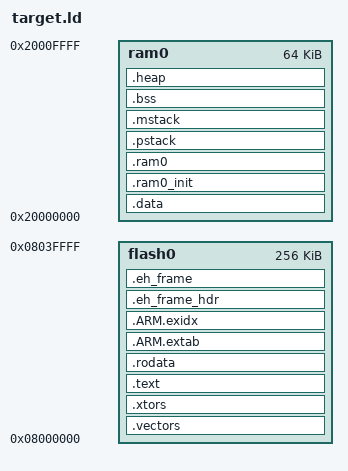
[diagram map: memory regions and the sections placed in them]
/*
    ChibiOS - Copyright (C) 2006..2016 Giovanni Di Sirio

    Licensed under the Apache License, Version 2.0 (the "License");
    you may not use this file except in compliance with the License.
    You may obtain a copy of the License at

        http://www.apache.org/licenses/LICENSE-2.0

    Unless required by applicable law or agreed to in writing, software
    distributed under the License is distributed on an "AS IS" BASIS,
    WITHOUT WARRANTIES OR CONDITIONS OF ANY KIND, either express or implied.
    See the License for the specific language governing permissions and
    limitations under the License.
*/

MEMORY
{
    flash0  : org = 0x08000000, len = 256k
    ram0    : org = 0x20000000, len = 64k
}

__ram0_start__          = ORIGIN(ram0);
__ram0_size__           = LENGTH(ram0);
__ram0_end__            = __ram0_start__ + __ram0_size__;
__main_stack_size__     = 0x400;
__process_stack_size__  = 0x400;

ENTRY (Reset_Handler)

SECTIONS
{
    .vectors : ALIGN(16)
    {
        KEEP(*(.vectors))
    } > flash0

    .xtors : ALIGN(4)
    {
        __init_array_start = .;
        KEEP(*(SORT(.init_array.*)))
        KEEP(*(.init_array))
        __init_array_end = .;
        __fini_array_start = .;
        KEEP(*(.fini_array))
        KEEP(*(SORT(.fini_array.*)))
        __fini_array_end = .;
    } > flash0

    .text : ALIGN(16)
    {
        *(.text)
        *(.text.*)
        *(.glue_7t)
        *(.glue_7)
        *(.gcc*)
    } > flash0

    .rodata : ALIGN(4)
    {
        . = ALIGN(4);
        __rodata_base__ = .;
        *(.rodata)
        *(.rodata.*)
        . = ALIGN(4);
        __rodata_end__ = .;
    } > flash0

    .ARM.extab :
    {
        *(.ARM.extab* .gnu.linkonce.armextab.*)
    } > flash0

    .ARM.exidx : {
        __exidx_start = .;
        *(.ARM.exidx* .gnu.linkonce.armexidx.*)
        __exidx_end = .;
     } > flash0

    .eh_frame_hdr :
    {
        *(.eh_frame_hdr)
    } > flash0

    .eh_frame : ONLY_IF_RO
    {
        *(.eh_frame)
    } > flash0

    _eoflash0 = .;

    .data : AT(_eoflash0) ALIGN(4)
    {
        . = ALIGN(4);
        PROVIDE(_textdata = LOADADDR(.data));
        PROVIDE(_data = .);
        _textdata_start = LOADADDR(.data);
        _data_start = .;
        *(.data)
        *(.data.*)
        *(.ramtext)
        . = ALIGN(4);
        PROVIDE(_edata = .);
        _data_end = .;
    } > ram0

    .ram0_init : AT(_eoflash0 + SIZEOF(.data)) ALIGN(4)
    {
        . = ALIGN(4);
        _data_size = SIZEOF(.data);
        __ram0_init_text__ = LOADADDR(.ram0_init);
        __ram0_init__ = .;
        KEEP(*(.ram0_init))
        KEEP(*(.ram0_init.*))
        . = ALIGN(4);
        __ram0_init_end__ = .;
    } > ram0

    .ram0 (NOLOAD) : ALIGN(4)
    {
        . = ALIGN(4);
        __ram0_clear__ = .;
        *(.ram0_clear)
        *(.ram0_clear.*)
        . = ALIGN(4);
        __ram0_noinit__ = .;
        *(.ram0)
        *(.ram0.*)
        . = ALIGN(4);
        __ram0_free__ = .;
    } > ram0

    .pstack :
    {
        . = ALIGN(8);
        __process_stack_base__ = .;
        __main_thread_stack_base__ = .;
        . += __process_stack_size__;
        . = ALIGN(8);
        __process_stack_end__ = .;
        __main_thread_stack_end__ = .;
    } > ram0

    .mstack :
    {
        . = ALIGN(8);
        __main_stack_base__ = .;
        . += __main_stack_size__;
        . = ALIGN(8);
        __main_stack_end__ = .;
    } > ram0

    .bss (NOLOAD) : ALIGN(4)
    {
        . = ALIGN(4);
        _bss_start = .;
        *(.bss)
        *(.bss.*)
        *(COMMON)
        . = ALIGN(4);
        _bss_end = .;
        PROVIDE(end = .);
    } > ram0

    .heap (NOLOAD) :
    {
        . = ALIGN(8);
        __heap_base__ = .;
        . = ORIGIN(ram0) + LENGTH(ram0);
        __heap_end__ = .;
    } > ram0
}
